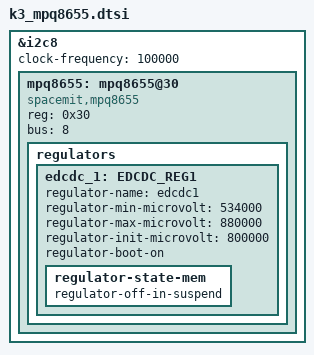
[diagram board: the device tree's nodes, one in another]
// SPDX-License-Identifier: (GPL-2.0 OR MIT)
/* Copyright (c) 2023 Spacemit, Inc */

&i2c8 {
	clock-frequency = <100000>;
	u-boot,dm-spl;
	status = "okay";

	mpq8655: mpq8655@30 {
		compatible = "spacemit,mpq8655";
		reg = <0x30>;
		bus = <8>;
		u-boot,dm-spl;

		regulators {
			u-boot,dm-spl;

			edcdc_1: EDCDC_REG1 {
				regulator-name = "edcdc1";
				regulator-min-microvolt = <534000>;
				regulator-max-microvolt = <880000>;
				regulator-init-microvolt = <800000>;
				regulator-boot-on;
				u-boot,dm-spl;
				regulator-state-mem {
					regulator-off-in-suspend;
				};
			};
		};
	};
};
